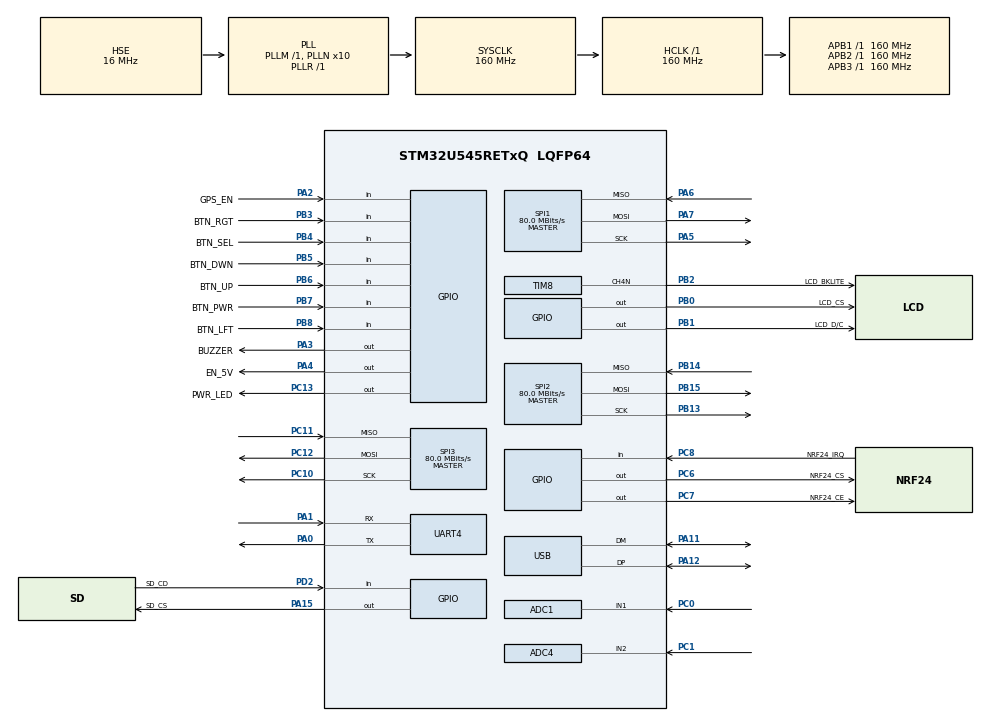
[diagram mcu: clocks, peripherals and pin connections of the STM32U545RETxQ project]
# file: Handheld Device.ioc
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ADC1.Channel-6\#ChannelRegularConversion=ADC_CHANNEL_1
ADC1.MonitoredBy-6\#ChannelRegularConversion=__NULL
ADC1.NbrOfConversionFlag=1
ADC1.OffsetNumber-6\#ChannelRegularConversion=ADC_OFFSET_NONE
ADC1.Rank-6\#ChannelRegularConversion=1
ADC1.SamplingTime-6\#ChannelRegularConversion=ADC_SAMPLETIME_5CYCLE
ADC1.master=1
ADC4.Channel-0\#ChannelRegularConversion=ADC_CHANNEL_2
ADC4.NbrOfConversionFlag=1
ADC4.OffsetNumber-0\#ChannelRegularConversion=ADC_OFFSET_NONE
ADC4.Rank-0\#ChannelRegularConversion=1
ADC4.RankArg-0\#ChannelRegularConversion=ADC4_REGULAR_RANK_1
ADC4.SamplingTime-0\#ChannelRegularConversion=ADC4_SAMPLINGTIME_COMMON_1
ADC4.SelectedChannel=ADC_CHANNEL_2
CORTEX_M33_NS.userName=CORTEX_M33
Mcu.Family=STM32U5
Mcu.Name=STM32U545RETxQ
Mcu.Package=LQFP64
NVIC.PriorityGroup=NVIC_PRIORITYGROUP_4
PA0.Mode=Asynchronous
PA0.Signal=UART4_TX
PA1.Mode=Asynchronous
PA1.Signal=UART4_RX
PA11.Mode=Host
PA11.Signal=USB_DM
PA12.Mode=Host
PA12.Signal=USB_DP
PA13\ (JTMS/SWDIO).Mode=Serial_Wire
PA13\ (JTMS/SWDIO).Signal=DEBUG_JTMS-SWDIO
PA14\ (JTCK/SWCLK).Mode=Serial_Wire
PA14\ (JTCK/SWCLK).Signal=DEBUG_JTCK-SWCLK
PA15\ (JTDI).GPIO_Label=SD_CS
PA15\ (JTDI).Signal=GPIO_Output
PA2.GPIO_Label=GPS_EN
PA2.Signal=GPIO_Input
PA3.GPIO_Label=BUZZER
PA3.Signal=GPIO_Output
PA4.GPIO_Label=EN_5V
PA4.Signal=GPIO_Output
PA5.Mode=Full_Duplex_Master
PA5.Signal=SPI1_SCK
PA6.Mode=Full_Duplex_Master
PA6.Signal=SPI1_MISO
PA7.Mode=Full_Duplex_Master
PA7.Signal=SPI1_MOSI
PB0.GPIO_Label=LCD_CS
PB0.Signal=GPIO_Output
PB1.GPIO_Label=LCD_D/C
PB1.Signal=GPIO_Output
PB13.Mode=Full_Duplex_Master
PB13.Signal=SPI2_SCK
PB14.Mode=Full_Duplex_Master
PB14.Signal=SPI2_MISO
PB15.Mode=Full_Duplex_Master
PB15.Signal=SPI2_MOSI
PB2.GPIO_Label=LCD_BKLITE
PB2.Mode=PWM Generation4 CH4N
PB2.Signal=TIM8_CH4N
PB3\ (JTDO/TRACESWO).GPIO_Label=BTN_RGT
PB3\ (JTDO/TRACESWO).Signal=GPIO_Input
PB4\ (NJTRST).GPIO_Label=BTN_SEL
PB4\ (NJTRST).Signal=GPIO_Input
PB5.GPIO_Label=BTN_DWN
PB5.Signal=GPIO_Input
PB6.GPIO_Label=BTN_UP
PB6.Signal=GPIO_Input
PB7.GPIO_Label=BTN_PWR
PB7.Signal=GPIO_Input
PB8.GPIO_Label=BTN_LFT
PB8.Signal=GPIO_Input
PC0.Mode=IN1-Single-Ended
PC0.Signal=ADC1_IN1
PC1.Mode=IN2
PC1.Signal=ADC4_IN2
PC10.Mode=Full_Duplex_Master
PC10.Signal=SPI3_SCK
PC11.Mode=Full_Duplex_Master
PC11.Signal=SPI3_MISO
PC12.Mode=Full_Duplex_Master
PC12.Signal=SPI3_MOSI
PC13.GPIO_Label=PWR_LED
PC13.Signal=GPIO_Output
PC6.GPIO_Label=NRF24_CS
PC6.Signal=GPIO_Output
PC7.GPIO_Label=NRF24_CE
PC7.Signal=GPIO_Output
PC8.GPIO_Label=NRF24_IRQ
PC8.Signal=GPIO_Input
PD2.GPIO_Label=SD_CD
PD2.Signal=GPIO_Input
PH0-OSC_IN\ (PH0).Mode=HSE-External-Oscillator
PH0-OSC_IN\ (PH0).Signal=RCC_OSC_IN
PH1-OSC_OUT\ (PH1).Mode=HSE-External-Oscillator
PH1-OSC_OUT\ (PH1).Signal=RCC_OSC_OUT
ProjectManager.HeapSize=0x200
ProjectManager.StackSize=0x400
ProjectManager.TargetToolchain=STM32CubeIDE
RCC.ADCFreq_Value=16000000
RCC.AHBFreq_Value=160000000
RCC.APB1Freq_Value=160000000
RCC.APB1TimFreq_Value=160000000
RCC.APB2Freq_Value=160000000
RCC.APB2TimFreq_Value=160000000
RCC.APB3Freq_Value=160000000
RCC.CortexFreq_Value=160000000
RCC.DACCLockSelectionVirtual=RCC_DAC1CLKSOURCE_LSI
RCC.DACCLockSelectionVirtualString=RCC_DAC1CLKSOURCE_LSI
RCC.EPOD_VALUE=16000000
RCC.HCLKFreq_Value=160000000
RCC.HSE_VALUE=16000000
RCC.HSI48_VALUE=48000000
RCC.HSI_VALUE=16000000
RCC.LSE_VALUE=32768
RCC.LSIDIV_VALUE=32000
RCC.MSIClockRange=RCC_MSIRANGE_0
RCC.MSI_VALUE=48000000
RCC.PLL1R=1
RCC.PLL2FRACN=0
RCC.PLL3FRACN=0
RCC.PLLFRACN=0
RCC.PLLN=10
RCC.PLLSourceVirtual=RCC_PLLSOURCE_HSE
RCC.SYSCLKFreq_VALUE=160000000
RCC.SYSCLKSource=RCC_SYSCLKSOURCE_PLLCLK
RCC.USBFreq_Value=48000000
RCC.VCOOutputFreq_Value=160000000
SPI1.CalculateBaudRate=80.0 MBits/s
SPI1.Direction=SPI_DIRECTION_2LINES
SPI1.Mode=SPI_MODE_MASTER
SPI1.VirtualType=VM_MASTER
SPI2.CalculateBaudRate=80.0 MBits/s
SPI2.Direction=SPI_DIRECTION_2LINES
SPI2.Mode=SPI_MODE_MASTER
SPI2.VirtualType=VM_MASTER
SPI3.CalculateBaudRate=80.0 MBits/s
SPI3.Direction=SPI_DIRECTION_2LINES
SPI3.Mode=SPI_MODE_MASTER
SPI3.VirtualType=VM_MASTER
TIM8.Channel-PWM\ Generation4\ CH4N=TIM_CHANNEL_4
VP_LPBAMQUEUE_VS_QUEUE.Mode=QUEUEMODE
VP_LPBAM_VS_SIG1.Mode=SmartRun
VP_LPBAM_VS_SIG4.Mode=LPDMA1
VP_MEMORYMAP_VS_MEMORYMAP.Mode=CurAppReg
VP_PWR_VS_SECSignals.Mode=Security/Privilege
VP_PWR_Vdda.Mode=isolationVdda
board=custom

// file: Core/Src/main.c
/* USER CODE BEGIN Header */
/**
  ******************************************************************************
  * @file           : main.c
  * @brief          : Main program body
  ******************************************************************************
  * @attention
  *
  * Copyright (c) 2024 STMicroelectronics.
  * All rights reserved.
  *
  * This software is licensed under terms that can be found in the LICENSE file
  * in the root directory of this software component.
  * If no LICENSE file comes with this software, it is provided AS-IS.
  *
  ******************************************************************************
  */
/* USER CODE END Header */
#include "main.h"

ADC_HandleTypeDef hadc1;
ADC_HandleTypeDef hadc4;

SPI_HandleTypeDef hspi1;
SPI_HandleTypeDef hspi2;
SPI_HandleTypeDef hspi3;

TIM_HandleTypeDef htim8;

UART_HandleTypeDef huart4;

HCD_HandleTypeDef hhcd_USB_DRD_FS;

void SystemClock_Config(void);
static void MX_GPIO_Init(void);
static void MX_SPI1_Init(void);
static void MX_SPI2_Init(void);
static void MX_SPI3_Init(void);
static void MX_USB_DRD_FS_HCD_Init(void);
static void MX_ADC1_Init(void);
static void MX_ADC4_Init(void);
static void MX_TIM8_Init(void);
static void MX_UART4_Init(void);

int main(void)
{

  /* MCU Configuration--------------------------------------------------------*/

  /* Reset of all peripherals, Initializes the Flash interface and the Systick. */
  HAL_Init();

  /* Configure the system clock */
  SystemClock_Config();

  /* Initialize all configured peripherals */
  MX_GPIO_Init();
  MX_SPI1_Init();
  MX_SPI2_Init();
  MX_SPI3_Init();
  MX_USB_DRD_FS_HCD_Init();
  MX_ADC1_Init();
  MX_ADC4_Init();
  MX_TIM8_Init();
  MX_UART4_Init();
  /* USER CODE BEGIN 2 */

  //Set the battery enable pin low
  HAL_GPIO_WritePin(GPIOA, EN_5V_Pin, GPIO_PIN_RESET);

  /* USER CODE END 2 */

  /* Infinite loop */
  /* USER CODE BEGIN WHILE */
  while (1)
  {
	  // Toggle the onboard LED on and off every 100ms
	  HAL_GPIO_WritePin(GPIOC, PWR_LED_Pin, GPIO_PIN_SET);
	  HAL_Delay(1000);
	  HAL_GPIO_WritePin(GPIOC, PWR_LED_Pin, GPIO_PIN_RESET);
	  HAL_Delay(1000);
    /* USER CODE END WHILE */

  }
}

void SystemClock_Config(void)
{
  RCC_OscInitTypeDef RCC_OscInitStruct = {0};
  RCC_ClkInitTypeDef RCC_ClkInitStruct = {0};

  /** Configure the main internal regulator output voltage
  */
  if (HAL_PWREx_ControlVoltageScaling(PWR_REGULATOR_VOLTAGE_SCALE1) != HAL_OK)
  {
    Error_Handler();
  }

  /** Initializes the CPU, AHB and APB buses clocks
  */
  RCC_OscInitStruct.OscillatorType = RCC_OSCILLATORTYPE_HSI48|RCC_OSCILLATORTYPE_HSI
                              |RCC_OSCILLATORTYPE_HSE;
  RCC_OscInitStruct.HSEState = RCC_HSE_ON;
  RCC_OscInitStruct.HSIState = RCC_HSI_ON;
  RCC_OscInitStruct.HSI48State = RCC_HSI48_ON;
  RCC_OscInitStruct.HSICalibrationValue = RCC_HSICALIBRATION_DEFAULT;
  RCC_OscInitStruct.PLL.PLLState = RCC_PLL_ON;
  RCC_OscInitStruct.PLL.PLLSource = RCC_PLLSOURCE_HSE;
  RCC_OscInitStruct.PLL.PLLMBOOST = RCC_PLLMBOOST_DIV1;
  RCC_OscInitStruct.PLL.PLLM = 1;
  RCC_OscInitStruct.PLL.PLLN = 10;
  RCC_OscInitStruct.PLL.PLLP = 2;
  RCC_OscInitStruct.PLL.PLLQ = 2;
  RCC_OscInitStruct.PLL.PLLR = 1;
  RCC_OscInitStruct.PLL.PLLRGE = RCC_PLLVCIRANGE_1;
  RCC_OscInitStruct.PLL.PLLFRACN = 0;
  if (HAL_RCC_OscConfig(&RCC_OscInitStruct) != HAL_OK)
  {
    Error_Handler();
  }

  /** Initializes the CPU, AHB and APB buses clocks
  */
  RCC_ClkInitStruct.ClockType = RCC_CLOCKTYPE_HCLK|RCC_CLOCKTYPE_SYSCLK
                              |RCC_CLOCKTYPE_PCLK1|RCC_CLOCKTYPE_PCLK2
                              |RCC_CLOCKTYPE_PCLK3;
  RCC_ClkInitStruct.SYSCLKSource = RCC_SYSCLKSOURCE_PLLCLK;
  RCC_ClkInitStruct.AHBCLKDivider = RCC_SYSCLK_DIV1;
  RCC_ClkInitStruct.APB1CLKDivider = RCC_HCLK_DIV1;
  RCC_ClkInitStruct.APB2CLKDivider = RCC_HCLK_DIV1;
  RCC_ClkInitStruct.APB3CLKDivider = RCC_HCLK_DIV1;

  if (HAL_RCC_ClockConfig(&RCC_ClkInitStruct, FLASH_LATENCY_4) != HAL_OK)
  {
    Error_Handler();
  }
}

static void MX_ADC1_Init(void)
{

  ADC_ChannelConfTypeDef sConfig = {0};

  /** Common config
  */
  hadc1.Instance = ADC1;
  hadc1.Init.ClockPrescaler = ADC_CLOCK_ASYNC_DIV1;
  hadc1.Init.Resolution = ADC_RESOLUTION_14B;
  hadc1.Init.GainCompensation = 0;
  hadc1.Init.DataAlign = ADC_DATAALIGN_RIGHT;
  hadc1.Init.ScanConvMode = ADC_SCAN_DISABLE;
  hadc1.Init.EOCSelection = ADC_EOC_SINGLE_CONV;
  hadc1.Init.LowPowerAutoWait = DISABLE;
  hadc1.Init.ContinuousConvMode = DISABLE;
  hadc1.Init.NbrOfConversion = 1;
  hadc1.Init.DiscontinuousConvMode = DISABLE;
  hadc1.Init.ExternalTrigConv = ADC_SOFTWARE_START;
  hadc1.Init.ExternalTrigConvEdge = ADC_EXTERNALTRIGCONVEDGE_NONE;
  hadc1.Init.DMAContinuousRequests = DISABLE;
  hadc1.Init.TriggerFrequencyMode = ADC_TRIGGER_FREQ_HIGH;
  hadc1.Init.Overrun = ADC_OVR_DATA_PRESERVED;
  hadc1.Init.LeftBitShift = ADC_LEFTBITSHIFT_NONE;
  hadc1.Init.ConversionDataManagement = ADC_CONVERSIONDATA_DR;
  hadc1.Init.OversamplingMode = DISABLE;
  if (HAL_ADC_Init(&hadc1) != HAL_OK)
  {
    Error_Handler();
  }

  /** Configure Regular Channel
  */
  sConfig.Channel = ADC_CHANNEL_1;
  sConfig.Rank = ADC_REGULAR_RANK_1;
  sConfig.SamplingTime = ADC_SAMPLETIME_5CYCLE;
  sConfig.SingleDiff = ADC_SINGLE_ENDED;
  sConfig.OffsetNumber = ADC_OFFSET_NONE;
  sConfig.Offset = 0;
  if (HAL_ADC_ConfigChannel(&hadc1, &sConfig) != HAL_OK)
  {
    Error_Handler();
  }

}

static void MX_ADC4_Init(void)
{

  ADC_ChannelConfTypeDef sConfig = {0};

  /** Common config
  */
  hadc4.Instance = ADC4;
  hadc4.Init.ClockPrescaler = ADC_CLOCK_ASYNC_DIV1;
  hadc4.Init.Resolution = ADC_RESOLUTION_12B;
  hadc4.Init.DataAlign = ADC_DATAALIGN_RIGHT;
  hadc4.Init.ScanConvMode = ADC4_SCAN_DISABLE;
  hadc4.Init.EOCSelection = ADC_EOC_SINGLE_CONV;
  hadc4.Init.LowPowerAutoPowerOff = ADC_LOW_POWER_NONE;
  hadc4.Init.LowPowerAutoWait = DISABLE;
  hadc4.Init.ContinuousConvMode = DISABLE;
  hadc4.Init.NbrOfConversion = 1;
  hadc4.Init.DiscontinuousConvMode = DISABLE;
  hadc4.Init.ExternalTrigConv = ADC_SOFTWARE_START;
  hadc4.Init.ExternalTrigConvEdge = ADC_EXTERNALTRIGCONVEDGE_NONE;
  hadc4.Init.DMAContinuousRequests = DISABLE;
  hadc4.Init.TriggerFrequencyMode = ADC_TRIGGER_FREQ_LOW;
  hadc4.Init.Overrun = ADC_OVR_DATA_PRESERVED;
  hadc4.Init.SamplingTimeCommon1 = ADC4_SAMPLETIME_1CYCLE_5;
  hadc4.Init.SamplingTimeCommon2 = ADC4_SAMPLETIME_1CYCLE_5;
  hadc4.Init.OversamplingMode = DISABLE;
  if (HAL_ADC_Init(&hadc4) != HAL_OK)
  {
    Error_Handler();
  }

  /** Configure Regular Channel
  */
  sConfig.Channel = ADC_CHANNEL_2;
  sConfig.Rank = ADC4_REGULAR_RANK_1;
  sConfig.SamplingTime = ADC4_SAMPLINGTIME_COMMON_1;
  sConfig.OffsetNumber = ADC_OFFSET_NONE;
  sConfig.Offset = 0;
  if (HAL_ADC_ConfigChannel(&hadc4, &sConfig) != HAL_OK)
  {
    Error_Handler();
  }

}

static void MX_SPI1_Init(void)
{

  SPI_AutonomousModeConfTypeDef HAL_SPI_AutonomousMode_Cfg_Struct = {0};

  /* SPI1 parameter configuration*/
  hspi1.Instance = SPI1;
  hspi1.Init.Mode = SPI_MODE_MASTER;
  hspi1.Init.Direction = SPI_DIRECTION_2LINES;
  hspi1.Init.DataSize = SPI_DATASIZE_4BIT;
  hspi1.Init.CLKPolarity = SPI_POLARITY_LOW;
  hspi1.Init.CLKPhase = SPI_PHASE_1EDGE;
  hspi1.Init.NSS = SPI_NSS_SOFT;
  hspi1.Init.BaudRatePrescaler = SPI_BAUDRATEPRESCALER_2;
  hspi1.Init.FirstBit = SPI_FIRSTBIT_MSB;
  hspi1.Init.TIMode = SPI_TIMODE_DISABLE;
  hspi1.Init.CRCCalculation = SPI_CRCCALCULATION_DISABLE;
  hspi1.Init.CRCPolynomial = 0x7;
  hspi1.Init.NSSPMode = SPI_NSS_PULSE_ENABLE;
  hspi1.Init.NSSPolarity = SPI_NSS_POLARITY_LOW;
  hspi1.Init.FifoThreshold = SPI_FIFO_THRESHOLD_01DATA;
  hspi1.Init.MasterSSIdleness = SPI_MASTER_SS_IDLENESS_00CYCLE;
  hspi1.Init.MasterInterDataIdleness = SPI_MASTER_INTERDATA_IDLENESS_00CYCLE;
  hspi1.Init.MasterReceiverAutoSusp = SPI_MASTER_RX_AUTOSUSP_DISABLE;
  hspi1.Init.MasterKeepIOState = SPI_MASTER_KEEP_IO_STATE_DISABLE;
  hspi1.Init.IOSwap = SPI_IO_SWAP_DISABLE;
  hspi1.Init.ReadyMasterManagement = SPI_RDY_MASTER_MANAGEMENT_INTERNALLY;
  hspi1.Init.ReadyPolarity = SPI_RDY_POLARITY_HIGH;
  if (HAL_SPI_Init(&hspi1) != HAL_OK)
  {
    Error_Handler();
  }
  HAL_SPI_AutonomousMode_Cfg_Struct.TriggerState = SPI_AUTO_MODE_DISABLE;
  HAL_SPI_AutonomousMode_Cfg_Struct.TriggerSelection = SPI_GRP1_GPDMA_CH0_TCF_TRG;
  HAL_SPI_AutonomousMode_Cfg_Struct.TriggerPolarity = SPI_TRIG_POLARITY_RISING;
  if (HAL_SPIEx_SetConfigAutonomousMode(&hspi1, &HAL_SPI_AutonomousMode_Cfg_Struct) != HAL_OK)
  {
    Error_Handler();
  }

}

static void MX_SPI2_Init(void)
{

  SPI_AutonomousModeConfTypeDef HAL_SPI_AutonomousMode_Cfg_Struct = {0};

  /* SPI2 parameter configuration*/
  hspi2.Instance = SPI2;
  hspi2.Init.Mode = SPI_MODE_MASTER;
  hspi2.Init.Direction = SPI_DIRECTION_2LINES;
  hspi2.Init.DataSize = SPI_DATASIZE_4BIT;
  hspi2.Init.CLKPolarity = SPI_POLARITY_LOW;
  hspi2.Init.CLKPhase = SPI_PHASE_1EDGE;
  hspi2.Init.NSS = SPI_NSS_SOFT;
  hspi2.Init.BaudRatePrescaler = SPI_BAUDRATEPRESCALER_2;
  hspi2.Init.FirstBit = SPI_FIRSTBIT_MSB;
  hspi2.Init.TIMode = SPI_TIMODE_DISABLE;
  hspi2.Init.CRCCalculation = SPI_CRCCALCULATION_DISABLE;
  hspi2.Init.CRCPolynomial = 0x7;
  hspi2.Init.NSSPMode = SPI_NSS_PULSE_ENABLE;
  hspi2.Init.NSSPolarity = SPI_NSS_POLARITY_LOW;
  hspi2.Init.FifoThreshold = SPI_FIFO_THRESHOLD_01DATA;
  hspi2.Init.MasterSSIdleness = SPI_MASTER_SS_IDLENESS_00CYCLE;
  hspi2.Init.MasterInterDataIdleness = SPI_MASTER_INTERDATA_IDLENESS_00CYCLE;
  hspi2.Init.MasterReceiverAutoSusp = SPI_MASTER_RX_AUTOSUSP_DISABLE;
  hspi2.Init.MasterKeepIOState = SPI_MASTER_KEEP_IO_STATE_DISABLE;
  hspi2.Init.IOSwap = SPI_IO_SWAP_DISABLE;
  hspi2.Init.ReadyMasterManagement = SPI_RDY_MASTER_MANAGEMENT_INTERNALLY;
  hspi2.Init.ReadyPolarity = SPI_RDY_POLARITY_HIGH;
  if (HAL_SPI_Init(&hspi2) != HAL_OK)
  {
    Error_Handler();
  }
  HAL_SPI_AutonomousMode_Cfg_Struct.TriggerState = SPI_AUTO_MODE_DISABLE;
  HAL_SPI_AutonomousMode_Cfg_Struct.TriggerSelection = SPI_GRP1_GPDMA_CH0_TCF_TRG;
  HAL_SPI_AutonomousMode_Cfg_Struct.TriggerPolarity = SPI_TRIG_POLARITY_RISING;
  if (HAL_SPIEx_SetConfigAutonomousMode(&hspi2, &HAL_SPI_AutonomousMode_Cfg_Struct) != HAL_OK)
  {
    Error_Handler();
  }

}

static void MX_SPI3_Init(void)
{

  SPI_AutonomousModeConfTypeDef HAL_SPI_AutonomousMode_Cfg_Struct = {0};

  /* SPI3 parameter configuration*/
  hspi3.Instance = SPI3;
  hspi3.Init.Mode = SPI_MODE_MASTER;
  hspi3.Init.Direction = SPI_DIRECTION_2LINES;
  hspi3.Init.DataSize = SPI_DATASIZE_8BIT;
  hspi3.Init.CLKPolarity = SPI_POLARITY_LOW;
  hspi3.Init.CLKPhase = SPI_PHASE_1EDGE;
  hspi3.Init.NSS = SPI_NSS_SOFT;
  hspi3.Init.BaudRatePrescaler = SPI_BAUDRATEPRESCALER_2;
  hspi3.Init.FirstBit = SPI_FIRSTBIT_MSB;
  hspi3.Init.TIMode = SPI_TIMODE_DISABLE;
  hspi3.Init.CRCCalculation = SPI_CRCCALCULATION_DISABLE;
  hspi3.Init.CRCPolynomial = 0x7;
  hspi3.Init.NSSPMode = SPI_NSS_PULSE_ENABLE;
  hspi3.Init.NSSPolarity = SPI_NSS_POLARITY_LOW;
  hspi3.Init.FifoThreshold = SPI_FIFO_THRESHOLD_01DATA;
  hspi3.Init.MasterSSIdleness = SPI_MASTER_SS_IDLENESS_00CYCLE;
  hspi3.Init.MasterInterDataIdleness = SPI_MASTER_INTERDATA_IDLENESS_00CYCLE;
  hspi3.Init.MasterReceiverAutoSusp = SPI_MASTER_RX_AUTOSUSP_DISABLE;
  hspi3.Init.MasterKeepIOState = SPI_MASTER_KEEP_IO_STATE_DISABLE;
  hspi3.Init.IOSwap = SPI_IO_SWAP_DISABLE;
  hspi3.Init.ReadyMasterManagement = SPI_RDY_MASTER_MANAGEMENT_INTERNALLY;
  hspi3.Init.ReadyPolarity = SPI_RDY_POLARITY_HIGH;
  if (HAL_SPI_Init(&hspi3) != HAL_OK)
  {
    Error_Handler();
  }
  HAL_SPI_AutonomousMode_Cfg_Struct.TriggerState = SPI_AUTO_MODE_DISABLE;
  HAL_SPI_AutonomousMode_Cfg_Struct.TriggerSelection = SPI_GRP2_LPDMA_CH0_TCF_TRG;
  HAL_SPI_AutonomousMode_Cfg_Struct.TriggerPolarity = SPI_TRIG_POLARITY_RISING;
  if (HAL_SPIEx_SetConfigAutonomousMode(&hspi3, &HAL_SPI_AutonomousMode_Cfg_Struct) != HAL_OK)
  {
    Error_Handler();
  }

}

static void MX_TIM8_Init(void)
{

  TIM_MasterConfigTypeDef sMasterConfig = {0};
  TIM_OC_InitTypeDef sConfigOC = {0};
  TIM_BreakDeadTimeConfigTypeDef sBreakDeadTimeConfig = {0};

  htim8.Instance = TIM8;
  htim8.Init.Prescaler = 0;
  htim8.Init.CounterMode = TIM_COUNTERMODE_UP;
  htim8.Init.Period = 65535;
  htim8.Init.ClockDivision = TIM_CLOCKDIVISION_DIV1;
  htim8.Init.RepetitionCounter = 0;
  htim8.Init.AutoReloadPreload = TIM_AUTORELOAD_PRELOAD_DISABLE;
  if (HAL_TIM_PWM_Init(&htim8) != HAL_OK)
  {
    Error_Handler();
  }
  sMasterConfig.MasterOutputTrigger = TIM_TRGO_RESET;
  sMasterConfig.MasterOutputTrigger2 = TIM_TRGO2_RESET;
  sMasterConfig.MasterSlaveMode = TIM_MASTERSLAVEMODE_DISABLE;
  if (HAL_TIMEx_MasterConfigSynchronization(&htim8, &sMasterConfig) != HAL_OK)
  {
    Error_Handler();
  }
  sConfigOC.OCMode = TIM_OCMODE_PWM1;
  sConfigOC.Pulse = 0;
  sConfigOC.OCPolarity = TIM_OCPOLARITY_HIGH;
  sConfigOC.OCNPolarity = TIM_OCNPOLARITY_HIGH;
  sConfigOC.OCFastMode = TIM_OCFAST_DISABLE;
  sConfigOC.OCIdleState = TIM_OCIDLESTATE_RESET;
  sConfigOC.OCNIdleState = TIM_OCNIDLESTATE_RESET;
  if (HAL_TIM_PWM_ConfigChannel(&htim8, &sConfigOC, TIM_CHANNEL_4) != HAL_OK)
  {
    Error_Handler();
  }
  sBreakDeadTimeConfig.OffStateRunMode = TIM_OSSR_DISABLE;
  sBreakDeadTimeConfig.OffStateIDLEMode = TIM_OSSI_DISABLE;
  sBreakDeadTimeConfig.LockLevel = TIM_LOCKLEVEL_OFF;
  sBreakDeadTimeConfig.DeadTime = 0;
  sBreakDeadTimeConfig.BreakState = TIM_BREAK_DISABLE;
  sBreakDeadTimeConfig.BreakPolarity = TIM_BREAKPOLARITY_HIGH;
  sBreakDeadTimeConfig.BreakFilter = 0;
  sBreakDeadTimeConfig.BreakAFMode = TIM_BREAK_AFMODE_INPUT;
  sBreakDeadTimeConfig.Break2State = TIM_BREAK2_DISABLE;
  sBreakDeadTimeConfig.Break2Polarity = TIM_BREAK2POLARITY_HIGH;
  sBreakDeadTimeConfig.Break2Filter = 0;
  sBreakDeadTimeConfig.Break2AFMode = TIM_BREAK_AFMODE_INPUT;
  sBreakDeadTimeConfig.AutomaticOutput = TIM_AUTOMATICOUTPUT_DISABLE;
  if (HAL_TIMEx_ConfigBreakDeadTime(&htim8, &sBreakDeadTimeConfig) != HAL_OK)
  {
    Error_Handler();
  }
  HAL_TIM_MspPostInit(&htim8);

}

static void MX_UART4_Init(void)
{

  huart4.Instance = UART4;
  huart4.Init.BaudRate = 115200;
  huart4.Init.WordLength = UART_WORDLENGTH_8B;
  huart4.Init.StopBits = UART_STOPBITS_1;
  huart4.Init.Parity = UART_PARITY_NONE;
  huart4.Init.Mode = UART_MODE_TX_RX;
  huart4.Init.HwFlowCtl = UART_HWCONTROL_NONE;
  huart4.Init.OverSampling = UART_OVERSAMPLING_16;
  huart4.Init.OneBitSampling = UART_ONE_BIT_SAMPLE_DISABLE;
  huart4.Init.ClockPrescaler = UART_PRESCALER_DIV1;
  huart4.AdvancedInit.AdvFeatureInit = UART_ADVFEATURE_NO_INIT;
  if (HAL_UART_Init(&huart4) != HAL_OK)
  {
    Error_Handler();
  }
  if (HAL_UARTEx_SetTxFifoThreshold(&huart4, UART_TXFIFO_THRESHOLD_1_8) != HAL_OK)
  {
    Error_Handler();
  }
  if (HAL_UARTEx_SetRxFifoThreshold(&huart4, UART_RXFIFO_THRESHOLD_1_8) != HAL_OK)
  {
    Error_Handler();
  }
  if (HAL_UARTEx_DisableFifoMode(&huart4) != HAL_OK)
  {
    Error_Handler();
  }

}

static void MX_USB_DRD_FS_HCD_Init(void)
{

  hhcd_USB_DRD_FS.Instance = USB_DRD_FS;
  hhcd_USB_DRD_FS.Init.dev_endpoints = 8;
  hhcd_USB_DRD_FS.Init.Host_channels = 8;
  hhcd_USB_DRD_FS.Init.speed = HCD_SPEED_FULL;
  hhcd_USB_DRD_FS.Init.phy_itface = HCD_PHY_EMBEDDED;
  hhcd_USB_DRD_FS.Init.Sof_enable = DISABLE;
  hhcd_USB_DRD_FS.Init.low_power_enable = DISABLE;
  hhcd_USB_DRD_FS.Init.vbus_sensing_enable = DISABLE;
  hhcd_USB_DRD_FS.Init.bulk_doublebuffer_enable = DISABLE;
  hhcd_USB_DRD_FS.Init.iso_singlebuffer_enable = DISABLE;
  if (HAL_HCD_Init(&hhcd_USB_DRD_FS) != HAL_OK)
  {
    Error_Handler();
  }

}

static void MX_GPIO_Init(void)
{
  GPIO_InitTypeDef GPIO_InitStruct = {0};

  /* GPIO Ports Clock Enable */
  __HAL_RCC_GPIOC_CLK_ENABLE();
  __HAL_RCC_GPIOH_CLK_ENABLE();
  __HAL_RCC_GPIOA_CLK_ENABLE();
  __HAL_RCC_GPIOB_CLK_ENABLE();
  __HAL_RCC_GPIOD_CLK_ENABLE();

  /*Configure GPIO pin Output Level */
  HAL_GPIO_WritePin(GPIOC, PWR_LED_Pin|NRF24_CS_Pin|NRF24_CE_Pin, GPIO_PIN_RESET);

  /*Configure GPIO pin Output Level */
  HAL_GPIO_WritePin(GPIOA, BUZZER_Pin|EN_5V_Pin|SD_CS_Pin, GPIO_PIN_RESET);

  /*Configure GPIO pin Output Level */
  HAL_GPIO_WritePin(GPIOB, LCD_CS_Pin|LCD_D_C_Pin, GPIO_PIN_RESET);

  /*Configure GPIO pins : PWR_LED_Pin NRF24_CS_Pin NRF24_CE_Pin */
  GPIO_InitStruct.Pin = PWR_LED_Pin|NRF24_CS_Pin|NRF24_CE_Pin;
  GPIO_InitStruct.Mode = GPIO_MODE_OUTPUT_PP;
  GPIO_InitStruct.Pull = GPIO_NOPULL;
  GPIO_InitStruct.Speed = GPIO_SPEED_FREQ_LOW;
  HAL_GPIO_Init(GPIOC, &GPIO_InitStruct);

  /*Configure GPIO pin : GPS_EN_Pin */
  GPIO_InitStruct.Pin = GPS_EN_Pin;
  GPIO_InitStruct.Mode = GPIO_MODE_INPUT;
  GPIO_InitStruct.Pull = GPIO_NOPULL;
  HAL_GPIO_Init(GPS_EN_GPIO_Port, &GPIO_InitStruct);

  /*Configure GPIO pins : BUZZER_Pin EN_5V_Pin SD_CS_Pin */
  GPIO_InitStruct.Pin = BUZZER_Pin|EN_5V_Pin|SD_CS_Pin;
  GPIO_InitStruct.Mode = GPIO_MODE_OUTPUT_PP;
  GPIO_InitStruct.Pull = GPIO_NOPULL;
  GPIO_InitStruct.Speed = GPIO_SPEED_FREQ_LOW;
  HAL_GPIO_Init(GPIOA, &GPIO_InitStruct);

  /*Configure GPIO pins : LCD_CS_Pin LCD_D_C_Pin */
  GPIO_InitStruct.Pin = LCD_CS_Pin|LCD_D_C_Pin;
  GPIO_InitStruct.Mode = GPIO_MODE_OUTPUT_PP;
  GPIO_InitStruct.Pull = GPIO_NOPULL;
  GPIO_InitStruct.Speed = GPIO_SPEED_FREQ_LOW;
  HAL_GPIO_Init(GPIOB, &GPIO_InitStruct);

  /*Configure GPIO pin : NRF24_IRQ_Pin */
  GPIO_InitStruct.Pin = NRF24_IRQ_Pin;
  GPIO_InitStruct.Mode = GPIO_MODE_INPUT;
  GPIO_InitStruct.Pull = GPIO_NOPULL;
  HAL_GPIO_Init(NRF24_IRQ_GPIO_Port, &GPIO_InitStruct);

  /*Configure GPIO pin : SD_CD_Pin */
  GPIO_InitStruct.Pin = SD_CD_Pin;
  GPIO_InitStruct.Mode = GPIO_MODE_INPUT;
  GPIO_InitStruct.Pull = GPIO_NOPULL;
  HAL_GPIO_Init(SD_CD_GPIO_Port, &GPIO_InitStruct);

  /*Configure GPIO pins : BTN_RGT_Pin BTN_SEL_Pin BTN_DWN_Pin BTN_UP_Pin
                           BTN_PWR_Pin BTN_LFT_Pin */
  GPIO_InitStruct.Pin = BTN_RGT_Pin|BTN_SEL_Pin|BTN_DWN_Pin|BTN_UP_Pin
                          |BTN_PWR_Pin|BTN_LFT_Pin;
  GPIO_InitStruct.Mode = GPIO_MODE_INPUT;
  GPIO_InitStruct.Pull = GPIO_NOPULL;
  HAL_GPIO_Init(GPIOB, &GPIO_InitStruct);

}

void Error_Handler(void)
{
  __disable_irq();
  while (1)
  {
  }
}
